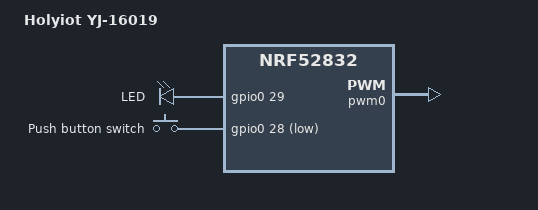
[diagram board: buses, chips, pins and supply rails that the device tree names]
/*
 * Copyright (c) 2019 Henrik Brix Andersen <henrik@brixandersen.dk>
 *
 * SPDX-License-Identifier: Apache-2.0
 */

/dts-v1/;
#include <nordic/nrf52832_qfaa.dtsi>
#include <nordic/nrf52840_partition.dtsi>
#include "holyiot_yj16019-pinctrl.dtsi"
#include <zephyr/dt-bindings/input/input-event-codes.h>

/ {
	model = "Holyiot YJ-16019";
	compatible = "holyiot,yj-16019";

	leds {
		compatible = "gpio-leds";
		led0: led_0 {
			gpios = <&gpio0 29 GPIO_ACTIVE_HIGH>;
			label = "LED";
		};
	};

	buttons {
		compatible = "gpio-keys";
		button0: button_0 {
			gpios = <&gpio0 28 GPIO_ACTIVE_LOW>;
			label = "Push button switch";
			zephyr,code = <INPUT_KEY_0>;
		};
	};

	/* These aliases are provided for compatibility with samples */
	aliases {
		sw0 = &button0;
		led0 = &led0;
		watchdog0 = &wdt0;
	};
};

&gpiote {
	status = "okay";
};

&gpio0 {
	status = "okay";
};

&pwm0 {
	status = "okay";
	pinctrl-0 = <&pwm0_default>;
	pinctrl-1 = <&pwm0_sleep>;
	pinctrl-names = "default", "sleep";
};
